# ioADuCM302x register map
Registers from a debugger description file.
Registers are 16-bit, access not given, no defined reset value unless marked. A register's access mark holds for its fields unless they carry their own. Addresses are absolute; registers are grouped by the start of their names; lines under a group give offsets from that group; [hi:lo] are bit positions; {n}, {i} and the like mark numbered series; 'fields as' and 'values as' point back to an identical list; <NAME> marks a mode.

## TMR0
0x40000000 TMR0_LOAD
0x40000004 TMR0_CURCNT
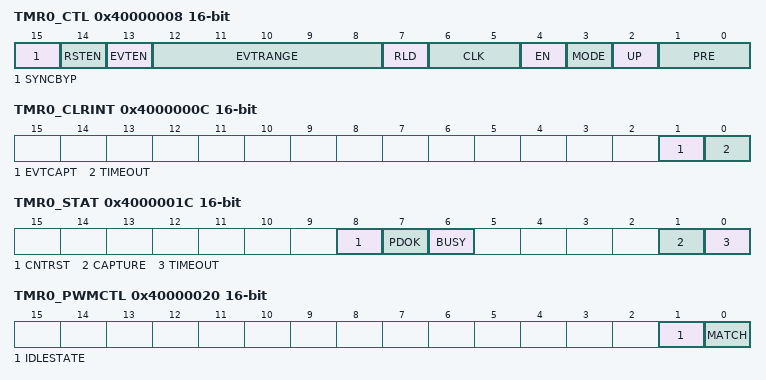
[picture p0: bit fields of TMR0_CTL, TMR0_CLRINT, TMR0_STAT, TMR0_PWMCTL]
0x40000008 TMR0_CTL
  [15] SYNCBYP, [14] RSTEN, [13] EVTEN, [12:8] EVTRANGE, [7] RLD, [6:5] CLK, [4] EN, [3] MODE, [2] UP, [1:0] PRE
0x4000000C TMR0_CLRINT
  [1] EVTCAPT, [0] TIMEOUT
0x40000010 TMR0_CAPTURE
0x40000014 TMR0_ALOAD
0x40000018 TMR0_ACURCNT
0x4000001C TMR0_STAT
  [8] CNTRST, [7] PDOK, [6] BUSY, [1] CAPTURE, [0] TIMEOUT
0x40000020 TMR0_PWMCTL
  [1] IDLESTATE, [0] MATCH
0x40000024 TMR0_PWMMATCH

## TMR1
0x40000400 TMR1_LOAD
0x40000404 TMR1_CURCNT
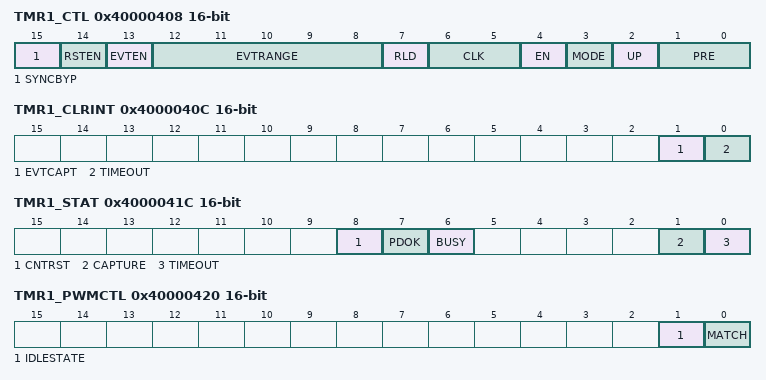
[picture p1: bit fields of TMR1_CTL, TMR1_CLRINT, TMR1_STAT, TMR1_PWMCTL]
0x40000408 TMR1_CTL
  [15] SYNCBYP, [14] RSTEN, [13] EVTEN, [12:8] EVTRANGE, [7] RLD, [6:5] CLK, [4] EN, [3] MODE, [2] UP, [1:0] PRE
0x4000040C TMR1_CLRINT
  [1] EVTCAPT, [0] TIMEOUT
0x40000410 TMR1_CAPTURE
0x40000414 TMR1_ALOAD
0x40000418 TMR1_ACURCNT
0x4000041C TMR1_STAT
  [8] CNTRST, [7] PDOK, [6] BUSY, [1] CAPTURE, [0] TIMEOUT
0x40000420 TMR1_PWMCTL
  [1] IDLESTATE, [0] MATCH
0x40000424 TMR1_PWMMATCH

## TMR2
0x40000800 TMR2_LOAD
0x40000804 TMR2_CURCNT
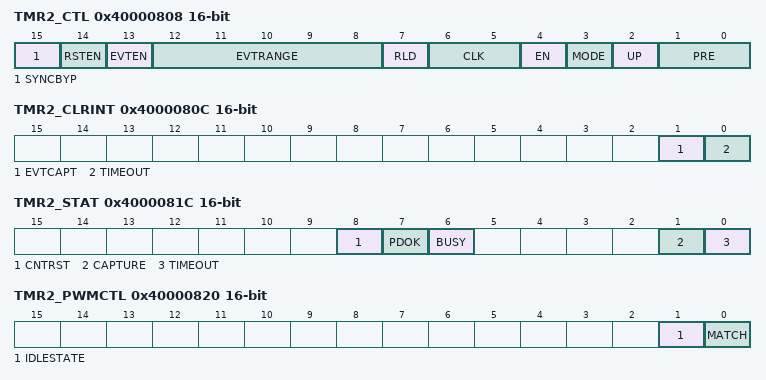
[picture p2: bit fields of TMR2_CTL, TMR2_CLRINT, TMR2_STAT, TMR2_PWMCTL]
0x40000808 TMR2_CTL
  [15] SYNCBYP, [14] RSTEN, [13] EVTEN, [12:8] EVTRANGE, [7] RLD, [6:5] CLK, [4] EN, [3] MODE, [2] UP, [1:0] PRE
0x4000080C TMR2_CLRINT
  [1] EVTCAPT, [0] TIMEOUT
0x40000810 TMR2_CAPTURE
0x40000814 TMR2_ALOAD
0x40000818 TMR2_ACURCNT
0x4000081C TMR2_STAT
  [8] CNTRST, [7] PDOK, [6] BUSY, [1] CAPTURE, [0] TIMEOUT
0x40000820 TMR2_PWMCTL
  [1] IDLESTATE, [0] MATCH
0x40000824 TMR2_PWMMATCH

## RTC0
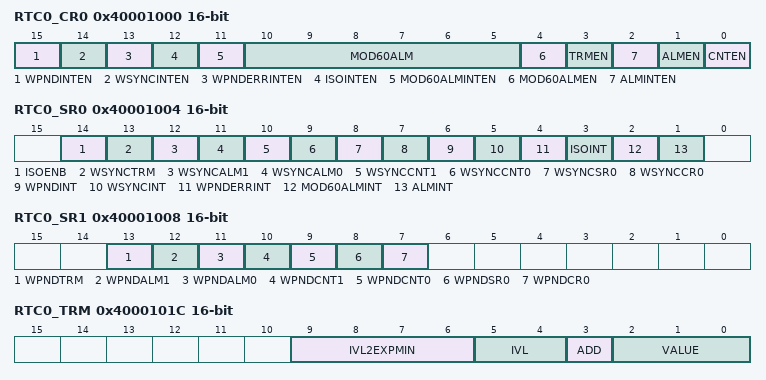
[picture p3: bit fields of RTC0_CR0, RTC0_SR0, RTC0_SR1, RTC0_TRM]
0x40001000 RTC0_CR0
  [15] WPNDINTEN, [14] WSYNCINTEN, [13] WPNDERRINTEN, [12] ISOINTEN, [11] MOD60ALMINTEN, [10:5] MOD60ALM, [4] MOD60ALMEN, [3] TRMEN, [2] ALMINTEN, [1] ALMEN, [0] CNTEN
0x40001004 RTC0_SR0
  [14] ISOENB, [13] WSYNCTRM, [12] WSYNCALM1, [11] WSYNCALM0, [10] WSYNCCNT1, [9] WSYNCCNT0, [8] WSYNCSR0, [7] WSYNCCR0, [6] WPNDINT, [5] WSYNCINT, [4] WPNDERRINT, [3] ISOINT, [2] MOD60ALMINT, [1] ALMINT
0x40001008 RTC0_SR1
  [13] WPNDTRM, [12] WPNDALM1, [11] WPNDALM0, [10] WPNDCNT1, [9] WPNDCNT0, [8] WPNDSR0, [7] WPNDCR0
0x4000100C RTC0_CNT0
0x40001010 RTC0_CNT1
0x40001014 RTC0_ALM0
0x40001018 RTC0_ALM1
0x4000101C RTC0_TRM
  [9:6] IVL2EXPMIN, [5:4] IVL, [3] ADD, [2:0] VALUE
0x40001020 RTC0_GWY
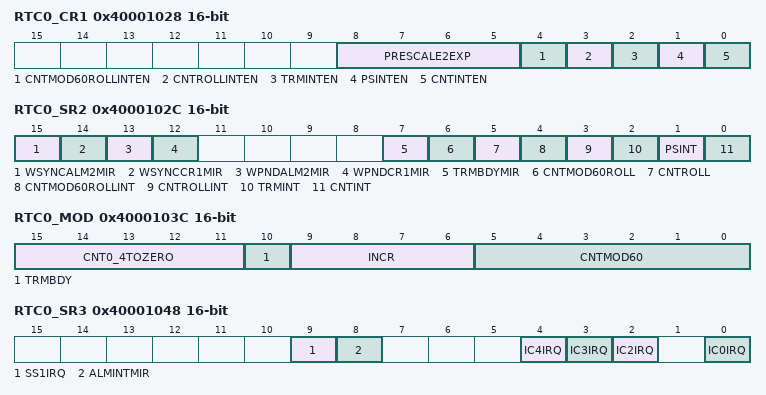
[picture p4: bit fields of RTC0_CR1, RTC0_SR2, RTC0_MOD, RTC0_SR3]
0x40001028 RTC0_CR1
  [8:5] PRESCALE2EXP, [4] CNTMOD60ROLLINTEN, [3] CNTROLLINTEN, [2] TRMINTEN, [1] PSINTEN, [0] CNTINTEN
0x4000102C RTC0_SR2
  [15] WSYNCALM2MIR, [14] WSYNCCR1MIR, [13] WPNDALM2MIR, [12] WPNDCR1MIR, [7] TRMBDYMIR, [6] CNTMOD60ROLL, [5] CNTROLL, [4] CNTMOD60ROLLINT, [3] CNTROLLINT, [2] TRMINT, [1] PSINT, [0] CNTINT
0x40001030 RTC0_SNAP0
0x40001034 RTC0_SNAP1
0x40001038 RTC0_SNAP2
  [14:0] VALUE
0x4000103C RTC0_MOD
  [15:11] CNT0_4TOZERO, [10] TRMBDY, [9:6] INCR, [5:0] CNTMOD60
0x40001040 RTC0_CNT2
  [14:0] VALUE
0x40001044 RTC0_ALM2
  [14:0] VALUE
0x40001048 RTC0_SR3
  [9] SS1IRQ, [8] ALMINTMIR, [4] IC4IRQ, [3] IC3IRQ, [2] IC2IRQ, [0] IC0IRQ
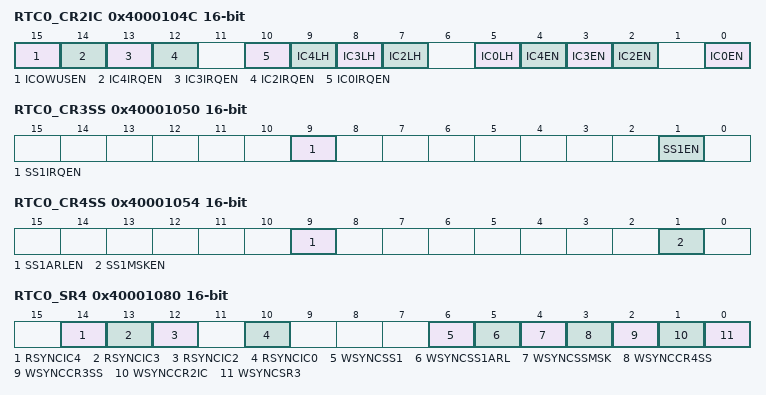
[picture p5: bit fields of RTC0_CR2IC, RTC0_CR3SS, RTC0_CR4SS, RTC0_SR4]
0x4000104C RTC0_CR2IC
  [15] ICOWUSEN, [14] IC4IRQEN, [13] IC3IRQEN, [12] IC2IRQEN, [10] IC0IRQEN, [9] IC4LH, [8] IC3LH, [7] IC2LH, [5] IC0LH, [4] IC4EN, [3] IC3EN, [2] IC2EN, [0] IC0EN
0x40001050 RTC0_CR3SS
  [9] SS1IRQEN, [1] SS1EN
0x40001054 RTC0_CR4SS
  [9] SS1ARLEN, [1] SS1MSKEN
0x40001058 RTC0_SSMSK
0x4000105C RTC0_SS1ARL
{0x4000105C+4i} RTC0_IC{i} (i=2..4)
0x40001070 RTC0_SS1
0x40001080 RTC0_SR4
  [14] RSYNCIC4, [13] RSYNCIC3, [12] RSYNCIC2, [10] RSYNCIC0, [6] WSYNCSS1, [5] WSYNCSS1ARL, [4] WSYNCSSMSK, [3] WSYNCCR4SS, [2] WSYNCCR3SS, [1] WSYNCCR2IC, [0] WSYNCSR3
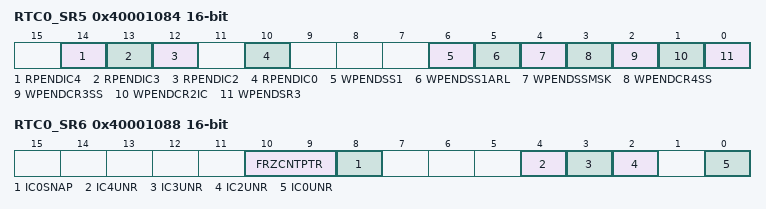
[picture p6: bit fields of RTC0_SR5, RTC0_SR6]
0x40001084 RTC0_SR5
  [14] RPENDIC4, [13] RPENDIC3, [12] RPENDIC2, [10] RPENDIC0, [6] WPENDSS1, [5] WPENDSS1ARL, [4] WPENDSSMSK, [3] WPENDCR4SS, [2] WPENDCR3SS, [1] WPENDCR2IC, [0] WPENDSR3
0x40001088 RTC0_SR6
  [10:9] FRZCNTPTR, [8] IC0SNAP, [4] IC4UNR, [3] IC3UNR, [2] IC2UNR, [0] IC0UNR
0x4000108C RTC0_SS1TGT
0x40001090 RTC0_FRZCNT

## Notices in the file
Copyright (c) 2014-2017 Analog Devices, Inc.  All Rights Reserved.
This software is proprietary and confidential to Analog Devices, Inc. and
its licensors.
